# S6E2CCxJ register map
Vendor: Cypress; File version: 2.0
CPU: CM4 r0p1, little endian, MPU, FPU, 4 interrupt priority bits
Registers are 32-bit, read-write, reset 0x0 unless marked. A register's access mark holds for its fields unless they carry their own. Offsets are from the block's base; [hi:lo] are bit positions; {n}, {i} and the like mark numbered series.

## BTIOSEL03 — Base Timer I/O Select
Base 0x40025100
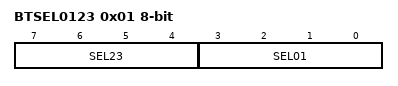
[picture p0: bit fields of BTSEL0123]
0x01 BTSEL0123 8-bit — I/O Select Register
  [7:4] SEL23 — I/O select bits for Ch.2/Ch.3
  [3:0] SEL01 — I/O select bits for Ch.0/Ch.1

## BTIOSEL47 — Base Timer I/O Select
Base 0x40025300
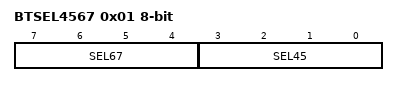
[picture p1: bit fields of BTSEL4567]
0x01 BTSEL4567 8-bit — I/O Select Register
  [7:4] SEL67 — I/O select bits for Ch.6/Ch.7
  [3:0] SEL45 — I/O select bits for Ch.4/Ch.5

## BTIOSEL8B — Base Timer I/O Select
Base 0x40025500
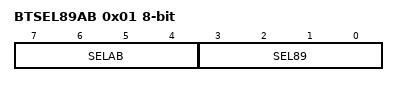
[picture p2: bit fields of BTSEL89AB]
0x01 BTSEL89AB 8-bit — I/O Select Register
  [7:4] SELAB — I/O select bits for Ch.A/Ch.B
  [3:0] SEL89 — I/O select bits for Ch.8/Ch.9

## BTIOSELCF — Base Timer I/O Select
Base 0x40025700
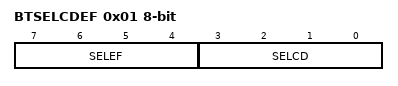
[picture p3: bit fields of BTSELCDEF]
0x01 BTSELCDEF 8-bit — I/O Select Register
  [7:4] SELEF — I/O select bits for Ch.E/Ch.F
  [3:0] SELCD — I/O select bits for Ch.C/Ch.D

## SBSSR — Software-based Simultaneous Startup Register
Base 0x40025F00
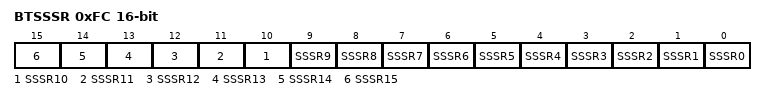
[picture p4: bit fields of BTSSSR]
0xFC BTSSSR 16-bit wo — Software-based Simultaneous Startup Register
  [n] SSSR{n} (n=0..15) — Bit{n} of BTSSSR

## QPRC0 — Quadrature Position/Revolution Counter 0
Base 0x40026000
Same registers: QPRC1 0x40026040, QPRC2 0x40026080, QPRC3 0x400260C0
0x00 QPCR 16-bit — QPRC Position Count Register
0x04 QRCR 16-bit — QPRC Revolution Count Register
0x08 QPCCR 16-bit — QPRC Position Counter Compare Register
0x0C QPRCR 16-bit — QPRC Position and Revolution Counter Compare Register
0x10 QMPR 16-bit reset 0xFFFF — QPRC Maximum Position Register
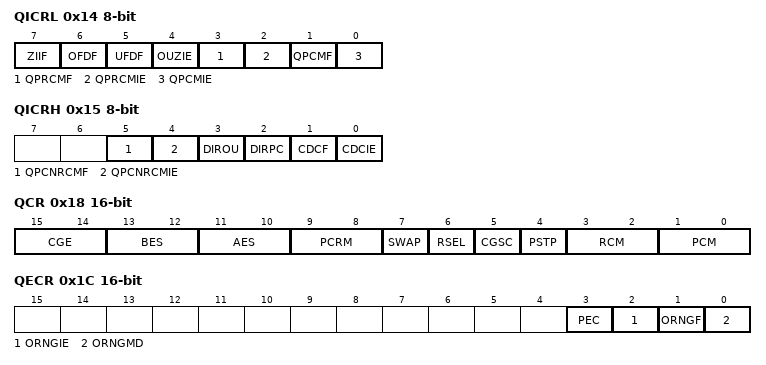
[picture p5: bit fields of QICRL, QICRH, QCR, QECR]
0x14 QICRL 8-bit — Low-Order Bytes of QPRC Interrupt Control Register
  [7] ZIIF — Zero index interrupt request flag bit
  [6] OFDF — Overflow interrupt request flag bit
  [5] UFDF — Underflow interrupt request flag bit
  [4] OUZIE — "Overflow, underflow, or zero index interrupt enable bit"
  [3] QPRCMF — PC and RC match interrupt request flag bit
  [2] QPRCMIE — PC and RC match interrupt enable bit
  [1] QPCMF — PC match interrupt request flag bit
  [0] QPCMIE — PC match interrupt enable bit
0x15 QICRH 8-bit — High-Order Bytes of QPRC Interrupt Control Register
  [5] QPCNRCMF — PC match and RC match interrupt request flag bit
  [4] QPCNRCMIE — PC match and RC match interrupt enable bit
  [3] DIROU ro — Last position counter flow direction bit
  [2] DIRPC ro — Last position counter direction bit
  [1] CDCF — Count inversion interrupt request flag bit
  [0] CDCIE — Count inversion interrupt enable bit
0x18 QCR 16-bit — QPRC Control Register
  [15:14] CGE — Detection edge selection bits
  [13:12] BES — BIN detection edge selection bits
  [11:10] AES — AIN detection edge selection bits
  [9:8] PCRM — Position counter reset mask bits
  [7] SWAP — Swap bit
  [6] RSEL — Register function selection bit
  [5] CGSC — Count clear or gate selection bit
  [4] PSTP — Position counter stop bit
  [3:2] RCM — Revolution counter mode bits
  [1:0] PCM — Position counter mode bits
0x1C QECR 16-bit — QPRC Extension Control Register
  [3] PEC — Phase edge change bit
  [2] ORNGIE — Outrange interrupt enable bit
  [1] ORNGF — Outrange interrupt request flag bit
  [0] ORNGMD — Outrange mode selection bit
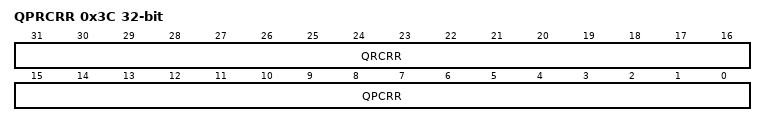
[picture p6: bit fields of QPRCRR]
0x3C QPRCRR ro — Quad Counter Position Rotation Count Register
  [31:16] QRCRR — Quad counter rotation count display bit
  [15:0] QPCRR — Quad counter position count display bit

## QPRC0_NF — Quadrature Position/Revolution Counter 0 Noise Filter
Base 0x40026100
Same registers: QPRC1_NF 0x40026110, QPRC2_NF 0x40026120, QPRC3_NF 0x40026130
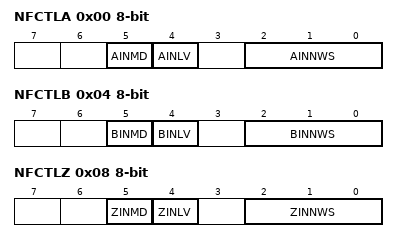
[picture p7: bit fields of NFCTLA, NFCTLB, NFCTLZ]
0x00 NFCTLA 8-bit — AIN Noise Control Register
  [5] AINMD — Mask bit
  [4] AINLV — Input invert bit
  [2:0] AINNWS — Noise filter width select bits
0x04 NFCTLB 8-bit — BIN Noise Control Register
  [5] BINMD — Mask bit
  [4] BINLV — Input invert bit
  [2:0] BINNWS — Noise filter width select bits
0x08 NFCTLZ 8-bit — ZIN Noise Control Register
  [5] ZINMD — Mask bit
  [4] ZINLV — Input invert bit
  [2:0] ZINNWS — Noise filter width select bits

## Notices in the file
Copyright (C) 2013-2015, Cypress Semiconductor Corporation. All Rights Reserved.
This software, including source code, documentation and related
materials ( "Software" ), is owned by Cypress Semiconductor
Corporation ( "Cypress" ) and is protected by and subject to worldwide
patent protection (United States and foreign), United States copyright
laws and international treaty provisions. Therefore, you may use this
Software only as provided in the license agreement accompanying the
software package from which you obtained this Software ( "EULA" ).
If no EULA applies, Cypress hereby grants you a personal, nonexclusive,
non-transferable license to copy, modify, and compile the
Software source code solely for use in connection with Cypress's
integrated circuit products. Any reproduction, modification, translation,
compilation, or representation of this Software except as specified
above is prohibited without the express written permission of Cypress.
Disclaimer: THIS SOFTWARE IS PROVIDED AS-IS, WITH NO
WARRANTY OF ANY KIND, EXPRESS OR IMPLIED, INCLUDING,
BUT NOT LIMITED TO, NONINFRINGEMENT, IMPLIED
WARRANTIES OF MERCHANTABILITY AND FITNESS FOR A
PARTICULAR PURPOSE. Cypress reserves the right to make
changes to the Software without notice. Cypress does not assume any
liability arising out of the application or use of the Software or any
product or circuit described in the Software. Cypress does not
authorize its products for use in any products where a malfunction or
failure of the Cypress product may reasonably be expected to result in
significant property damage, injury or death ( "High Risk Product" ). By
including Cypress's product in a High Risk Product, the manufacturer
of such system or application assumes all risk of such use and in doing
so agrees to indemnify Cypress against all liability.
